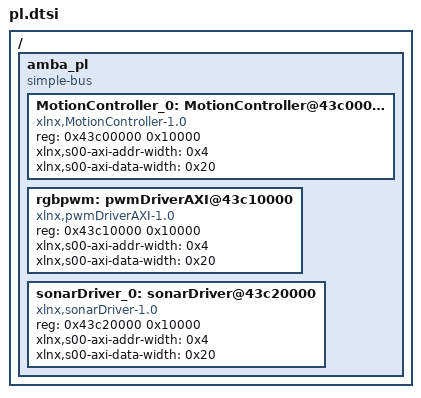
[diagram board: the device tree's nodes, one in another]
/*
 * CAUTION: This file is automatically generated by Xilinx.
 * Version:  
 * Today is: Thu Jan 10 21:36:24 2019
 */


/ {
	amba_pl: amba_pl {
		#address-cells = <1>;
		#size-cells = <1>;
		compatible = "simple-bus";
		ranges ;
		MotionController_0: MotionController@43c00000 {
			compatible = "xlnx,MotionController-1.0";
			reg = <0x43c00000 0x10000>;
			xlnx,s00-axi-addr-width = <0x4>;
			xlnx,s00-axi-data-width = <0x20>;
		};
		rgbpwm: pwmDriverAXI@43c10000 {
			compatible = "xlnx,pwmDriverAXI-1.0";
			reg = <0x43c10000 0x10000>;
			xlnx,s00-axi-addr-width = <0x4>;
			xlnx,s00-axi-data-width = <0x20>;
		};
		sonarDriver_0: sonarDriver@43c20000 {
			compatible = "xlnx,sonarDriver-1.0";
			reg = <0x43c20000 0x10000>;
			xlnx,s00-axi-addr-width = <0x4>;
			xlnx,s00-axi-data-width = <0x20>;
		};
	};
};
